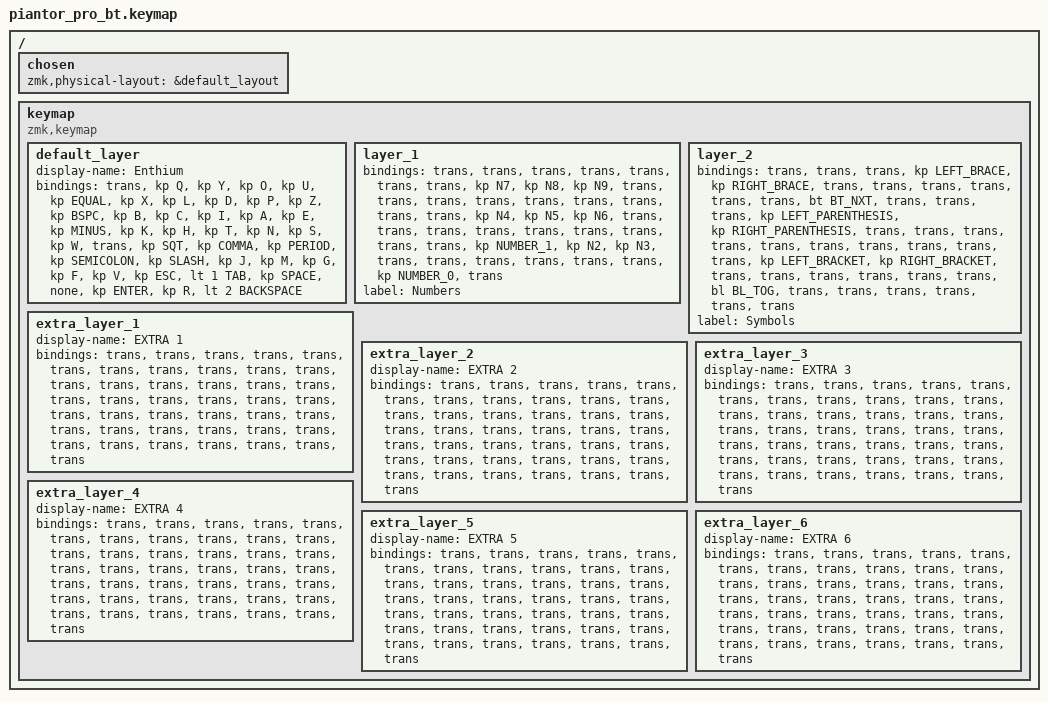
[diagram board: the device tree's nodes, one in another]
/*
 * Copyright (c) 2020 The ZMK Contributors
 *
 * SPDX-License-Identifier: MIT
 */

#include <behaviors.dtsi>
#include <dt-bindings/zmk/backlight.h>
#include <dt-bindings/zmk/bt.h>
#include <dt-bindings/zmk/keys.h>

/ {
    chosen { zmk,physical-layout = &default_layout; };
};

/ {
    keymap {
        compatible = "zmk,keymap";

        default_layer {
            display-name = "Enthium";

            // --------------------------------------------------------------------------------
            // |  TAB |  Q  |  W  |  E  |  R  |  T  |  Y  |  U   |  I  |  O  |  P  | BSPC |
            // | CTRL |  A  |  S  |  D  |  F  |  G  |  H  |  J   |  K  |  L  |  ;  |  '   |
            // | SHFT |  Z  |  X  |  C  |  V  |  B  |  N  |  M   |  ,  |  .  |  /  | ESC  |
            //                    | GUI | LWR | SPC | ENT | RSE  | ALT |

            bindings = <
&trans  &kp Q  &kp Y  &kp O  &kp U  &kp EQUAL  &kp X  &kp L  &kp D  &kp P  &kp Z  &kp BSPC  &kp B  &kp C  &kp I  &kp A  &kp E  &kp MINUS  &kp K  &kp H  &kp T  &kp N  &kp S  &kp W  &trans  &kp SQT  &kp COMMA  &kp PERIOD  &kp SEMICOLON  &kp SLASH  &kp J  &kp M  &kp G  &kp F  &kp V  &kp ESC  &lt 1 TAB  &kp SPACE  &none  &kp ENTER  &kp R  &lt 2 BACKSPACE
            >;
        };

        layer_1 {
            bindings = <
&trans  &trans  &trans  &trans  &trans  &trans  &trans  &kp N7  &kp N8  &kp N9  &trans  &trans  &trans  &trans  &trans  &trans  &trans  &trans  &trans  &kp N4  &kp N5  &kp N6  &trans  &trans  &trans  &trans  &trans  &trans  &trans  &trans  &trans  &kp NUMBER_1  &kp N2  &kp N3  &trans  &trans  &trans  &trans  &trans  &trans  &kp NUMBER_0  &trans
            >;

            label = "Numbers";
        };

        layer_2 {
            bindings = <
&trans  &trans  &trans  &kp LEFT_BRACE  &kp RIGHT_BRACE  &trans  &trans  &trans  &trans  &trans  &trans  &bt BT_NXT  &trans  &trans  &trans  &kp LEFT_PARENTHESIS  &kp RIGHT_PARENTHESIS  &trans  &trans  &trans  &trans  &trans  &trans  &trans  &trans  &trans  &trans  &kp LEFT_BRACKET  &kp RIGHT_BRACKET  &trans  &trans  &trans  &trans  &trans  &trans  &bl BL_TOG  &trans  &trans  &trans  &trans  &trans  &trans
            >;

            label = "Symbols";
        };

        extra_layer_1 {
            display-name = "EXTRA 1";
            bindings = <
&trans  &trans  &trans  &trans  &trans  &trans  &trans  &trans  &trans  &trans  &trans  &trans  &trans  &trans  &trans  &trans  &trans  &trans  &trans  &trans  &trans  &trans  &trans  &trans  &trans  &trans  &trans  &trans  &trans  &trans  &trans  &trans  &trans  &trans  &trans  &trans  &trans  &trans  &trans  &trans  &trans  &trans
            >;
        };

        extra_layer_2 {
            display-name = "EXTRA 2";
            bindings = <
&trans  &trans  &trans  &trans  &trans  &trans  &trans  &trans  &trans  &trans  &trans  &trans  &trans  &trans  &trans  &trans  &trans  &trans  &trans  &trans  &trans  &trans  &trans  &trans  &trans  &trans  &trans  &trans  &trans  &trans  &trans  &trans  &trans  &trans  &trans  &trans  &trans  &trans  &trans  &trans  &trans  &trans
            >;
        };

        extra_layer_3 {
            display-name = "EXTRA 3";
            bindings = <
&trans  &trans  &trans  &trans  &trans  &trans  &trans  &trans  &trans  &trans  &trans  &trans  &trans  &trans  &trans  &trans  &trans  &trans  &trans  &trans  &trans  &trans  &trans  &trans  &trans  &trans  &trans  &trans  &trans  &trans  &trans  &trans  &trans  &trans  &trans  &trans  &trans  &trans  &trans  &trans  &trans  &trans
            >;
        };

        extra_layer_4 {
            display-name = "EXTRA 4";
            bindings = <
&trans  &trans  &trans  &trans  &trans  &trans  &trans  &trans  &trans  &trans  &trans  &trans  &trans  &trans  &trans  &trans  &trans  &trans  &trans  &trans  &trans  &trans  &trans  &trans  &trans  &trans  &trans  &trans  &trans  &trans  &trans  &trans  &trans  &trans  &trans  &trans  &trans  &trans  &trans  &trans  &trans  &trans
            >;
        };

        extra_layer_5 {
            display-name = "EXTRA 5";
            bindings = <
&trans  &trans  &trans  &trans  &trans  &trans  &trans  &trans  &trans  &trans  &trans  &trans  &trans  &trans  &trans  &trans  &trans  &trans  &trans  &trans  &trans  &trans  &trans  &trans  &trans  &trans  &trans  &trans  &trans  &trans  &trans  &trans  &trans  &trans  &trans  &trans  &trans  &trans  &trans  &trans  &trans  &trans
            >;
        };

        extra_layer_6 {
            display-name = "EXTRA 6";
            bindings = <
&trans  &trans  &trans  &trans  &trans  &trans  &trans  &trans  &trans  &trans  &trans  &trans  &trans  &trans  &trans  &trans  &trans  &trans  &trans  &trans  &trans  &trans  &trans  &trans  &trans  &trans  &trans  &trans  &trans  &trans  &trans  &trans  &trans  &trans  &trans  &trans  &trans  &trans  &trans  &trans  &trans  &trans
            >;
        };
    };
};
